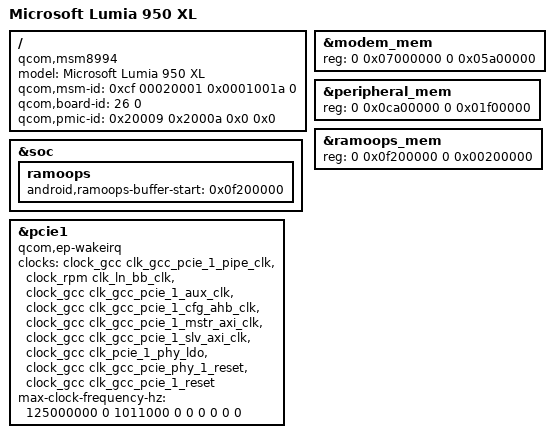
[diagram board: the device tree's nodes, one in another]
/* Copyright (c) 2014-2015, The Linux Foundation. All rights reserved.
 *
 * This program is free software; you can redistribute it and/or modify
 * it under the terms of the GNU General Public License version 2 and
 * only version 2 as published by the Free Software Foundation.
 *
 * This program is distributed in the hope that it will be useful,
 * but WITHOUT ANY WARRANTY; without even the implied warranty of
 * MERCHANTABILITY or FITNESS FOR A PARTICULAR PURPOSE.  See the
 * GNU General Public License for more details.
 */

/dts-v1/;

#include "../qcom/msm8994-v2.1.dtsi"
#include "../qcom/msm8994-pinctrl.dtsi"
#include "msm8994-chi.dtsi"

/ {
	model = "Microsoft Lumia 950 XL";
	compatible = "qcom,msm8994", "mmo,cityman";
	qcom,msm-id = <0xcf 00020001 0x0001001a 0>;
	qcom,board-id = <26 0>;
	qcom,pmic-id = <0x20009 0x2000a 0x0 0x0>;
};

/*
 * Keep the stock cityman modem load addresses out of Linux allocations.
 * The common ramoops address overlaps the stock modem image.
 */
&modem_mem {
	reg = <0 0x07000000 0 0x05a00000>;
};

&peripheral_mem {
	reg = <0 0x0ca00000 0 0x01f00000>;
};

&ramoops_mem {
	reg = <0 0x0f200000 0 0x00200000>;
};

&soc {
	ramoops {
		android,ramoops-buffer-start = <0x0f200000>;
	};
};

/* Reset the controller as well as the PHY before enumerating QCA6174. */
&pcie1 {
	/* CNSS must power the endpoint before the first enumeration. */
	qcom,ep-wakeirq;
	clocks = <&clock_gcc clk_gcc_pcie_1_pipe_clk>,
		<&clock_rpm clk_ln_bb_clk>,
		<&clock_gcc clk_gcc_pcie_1_aux_clk>,
		<&clock_gcc clk_gcc_pcie_1_cfg_ahb_clk>,
		<&clock_gcc clk_gcc_pcie_1_mstr_axi_clk>,
		<&clock_gcc clk_gcc_pcie_1_slv_axi_clk>,
		<&clock_gcc clk_pcie_1_phy_ldo>,
		<&clock_gcc clk_gcc_pcie_phy_1_reset>,
		<&clock_gcc clk_gcc_pcie_1_reset>;
	clock-names = "pcie_1_pipe_clk", "pcie_1_ref_clk_src",
		"pcie_1_aux_clk", "pcie_1_cfg_ahb_clk",
		"pcie_1_mstr_axi_clk", "pcie_1_slv_axi_clk",
		"pcie_1_ldo", "pcie_1_phy_reset", "core_reset";
	max-clock-frequency-hz = <125000000 0 1011000 0 0 0 0 0 0>;
};
